# FM33G0XX register map
File version: 1.0
CPU: SC000 r1p0, little endian, no MPU, no FPU, 3 interrupt priority bits
Registers are 32-bit, read-write, reset 0x0 unless marked. A register's access mark holds for its fields unless they carry their own. Offsets are from the block's base; [hi:lo] are bit positions; {n}, {i} and the like mark numbered series.

## ETxCNT — EXTENDED TIMER COUNTER Registers
Base 0x40013110
0x00 ET1CNT — ETIMER1 COUNTER REGISTER
  [15:0] ETxCNT — ETIMER COUNTER
0x04 ET2CNT — ETIMER2 COUNTER REGISTER
  [15:0] ETxCNT — ETIMER COUNTER
0x08 ET3CNT — ETIMER3 COUNTER REGISTER
  [15:0] ETxCNT — ETIMER COUNTER
0x0C ET4CNT — ETIMER4 COUNTER REGISTER
  [15:0] ETxCNT — ETIMER COUNTER

## LPTIM — LPTIM Registers
Base 0x40013400
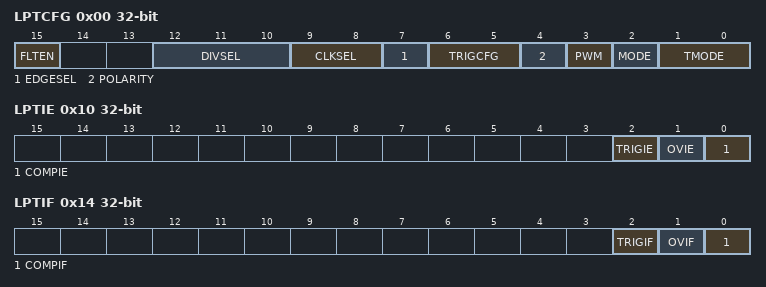
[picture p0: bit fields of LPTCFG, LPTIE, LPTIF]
0x00 LPTCFG — LPTIMER CONFIG REGISTER
  [15] FLTEN
    0=ENABLE DF; 1=DISABLE DF
  [12:10] DIVSEL — CLK DIVIDED SELECT
    0=DIV1; 1=DIV2; 2=DIV4; 3=DIV8; 4=DIV16; 5=DIV32; 6=DIV64; 7=DIV128
  [9:8] CLKSEL — CLK SOURCE SELECT
    0=LSCLK; 1=RCLP; 2=PCLK; 3=LPTIN
  [7] EDGESEL — EDGE SELECT
    0=POS; 1=NEG
  [6:5] TRIGCFG
    0=POS; 1=NEG; 2=BOTH; 3=BOTH
  [4] POLARITY
    0=POS; 1=NEG
  [3] PWM
    0=SQR; 1=PMW
  [2] MODE
    0=CONTINUOUS; 1=ONCE
  [1:0] TMODE
    0=OUT_CNT; 1=TRIG_CNT; 2=OUTER_SOURCE; 3=Timeout
0x04 LPTCNT — LPTIMER COUNTER REGISTER
  [15:0] LPTCNT
0x08 LPTCMP — LPTIMER COMPARE REGISTER
  [15:0] LPTCMP
0x0C LPTTARGET — LPTIMER TARGET REGISTER
  [15:0] LPTTARGET
0x10 LPTIE — LPTIMER IE REGISTER
  [2] TRIGIE, [1] OVIE, [0] COMPIE
0x14 LPTIF — LPTIMER IF REGISTER
  [2] TRIGIF, [1] OVIF, [0] COMPIF
0x18 LPTCTRL — LPTIMER CTRL REGISTER
  [0] LPTEN

## AES — AES Registers
Base 0x40013800
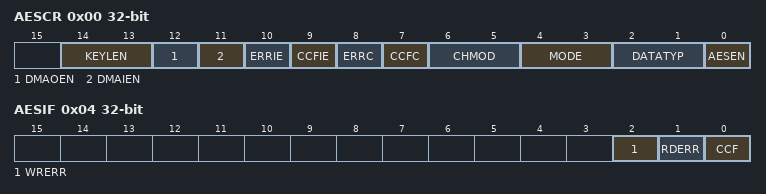
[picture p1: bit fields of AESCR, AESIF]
0x00 AESCR — AES CONTROL REGISTER
  [14:13] KEYLEN
    0=128bit; 1=192bit; 2=256bit; 3=REV
  [12] DMAOEN
  [11] DMAIEN
  [10] ERRIE
  [9] CCFIE
  [8] ERRC wo — ERR Clear
  [7] CCFC wo — CCF Clear
  [6:5] CHMOD
    0=ECB; 1=CBC; 2=CTR; 3=MultH
  [4:3] MODE
    0=ENCRYPT; 1=KEY_EXPANSION; 2=DECRYPT; 3=KEYEXP_DEC (KEY_EXPANSION + DECRYPT)
  [2:1] DATATYP
    0=32bit; 1=16bit; 2=8bit; 3=1bit
  [0] AESEN
0x04 AESIF
  [2] WRERR, [1] RDERR, [0] CCF
0x08 AESDIN — AES DATA INPUT REGISTER
0x0C AESDOUT — AES DATA OUTPUT REGISTER
{0x10+4i} AESKEY{i} (i=0..7)
  [31:0] AESKEY
{0x30+4i} AESIVR{i} (i=0..3) — AES INITIAL VECTOR{i} REGISTER
  [31:0] AESIVR

## TRNG — TRNG Registers
Base 0x40013C04
0x00 RNGOUT — TRNG OUTPUT REGISTER
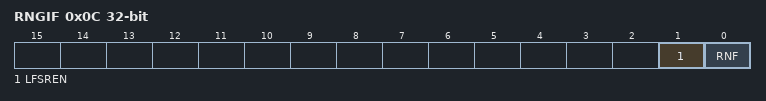
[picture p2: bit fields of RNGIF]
0x0C RNGIF — TRNG IF REGISTER
  [1] LFSREN ro, [0] RNF
0x10 CRCCON — CRC CONTROL REGISTER
  [0] CRCEN
0x14 CRCIN — CRC INPUT REGISTER
0x18 CRCIF — CRC complete REGISTER
  [0] CRCIF — CRCIN

## LPUART — LPUART Registers
Base 0x40010400
0x00 LPURXD — LPUART RECEIVE BUFF REGISTER
  [7:0] LPURXD — RECEIVED BUFF
0x04 LPUTXD — LPUART TRANS BUFF REGISTER
  [7:0] LPUTXD — TRANS BUFF
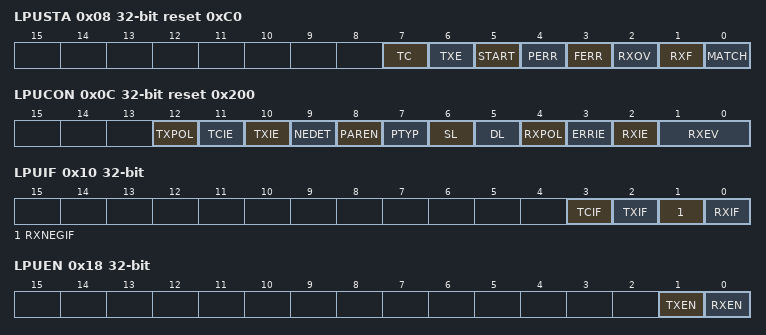
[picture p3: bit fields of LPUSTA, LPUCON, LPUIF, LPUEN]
0x08 LPUSTA reset 0xC0 — LPUART STATUS REGISTER
  [7] TC — TX COMPLETE
  [6] TXE — TX BUFF EMPTY
  [5] START — DETECT START Signal,WRITE 1 TO CLEAR
  [4] PERR — PARITY ERROR,WRITE 1 TO CLEAR
  [3] FERR — FRAME ERROR, WRITE 1 TO CLEAR
  [2] RXOV — RX BUFF OVERFLOW,WRITE 1 TO CLEAR
    0=NO_OVERFLOW; 1=OVERFLOW
  [1] RXF ro — RX BUFF FULL
    0=EMPTY; 1=FULL
  [0] MATCH — REC DATA MATCH COMPARE REGISTER ,WRITE 1 TO CLEAR
    0=NO_MATCH (NOT MATCH WITH COMPARE REGISTER); 1=MARCH
0x0C LPUCON reset 0x200 — LPUART CONFIG REGISTER
  [12] TXPOL — TX POLAR
    0=NO_REV (NOT REVERSE); 1=REV
  [11] TCIE
    0=DISABLE; 1=ENABLE
  [10] TXIE
    0=DISABLE; 1=ENABLE
  [9] NEDET — NEGATIVE EDGE DETECT ENABLE
    0=DISABLE; 1=ENABLE
  [8] PAREN — PARITY ENABLE
    0=DISABLE; 1=ENABLE
  [7] PTYP — PARITY TYPE
    0=EVEN; 1=ODD
  [6] SL — STOP LENGTH
    0=1BIT; 1=2BITS
  [5] DL — DATA LENGTH
    0=8BITS; 1=7BITS
  [4] RXPOL — RECEIVE POLAR
    0=NO_REV (NOT REVERSE); 1=REV (REVERSE)
  [3] ERRIE — RECEIVED ERROR IE
  [2] RXIE
  [1:0] RXEV — RX INTERUPT SOURCE SELECT
    0=START; 1=REC (1 BYTE DATA RECEIVED); 2=COMPARE; 3=RXEGFALL
0x10 LPUIF — LPUART IF REGISTER
  [3] TCIF — TX COMPLETE
  [2] TXIF
  [1] RXNEGIF — RX NEGATIVE EDGE DETECTED
  [0] RXIF
0x14 LPUBAUD — LPUART BAUDRATE REGISTER
  [2:0] BAUD — BAUDRATE SELECT
    0=9600BPS; 1=4800BPS; 2=2400BPS; 3=1200BPS; 4=600BPS; 5=300BPS; 6=300BPS; 7=300BPS
0x18 LPUEN — LPUART ENABLE REGISTER
  [1] TXEN — TX ENABLE
  [0] RXEN — RX ENABLE
0x1C COMPARE — COMPARE DATA REGISTER
  [7:0] COMPARE
0x20 MCTL — MODULATION CONTROL REGISTER
  [11:0] MCTL
